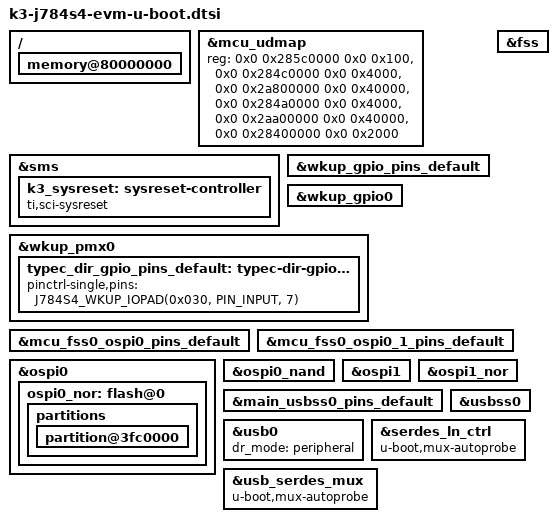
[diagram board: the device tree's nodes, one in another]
// SPDX-License-Identifier: GPL-2.0-only
/*
 * Copyright (C) 2023 Texas Instruments Incorporated - https://www.ti.com/
 */

#include "k3-j784s4-binman.dtsi"

/ {
	memory@80000000 {
		bootph-all;
	};
};

&mcu_udmap {
	reg =   <0x0 0x285c0000 0x0 0x100>,
		<0x0 0x284c0000 0x0 0x4000>,
		<0x0 0x2a800000 0x0 0x40000>,
		<0x0 0x284a0000 0x0 0x4000>,
		<0x0 0x2aa00000 0x0 0x40000>,
		<0x0 0x28400000 0x0 0x2000>;
	reg-names = "gcfg", "rchan", "rchanrt", "tchan",
		    "tchanrt", "rflow";
	bootph-pre-ram;
};

&sms {
	k3_sysreset: sysreset-controller {
		compatible = "ti,sci-sysreset";
		bootph-pre-ram;
	};
};

&wkup_gpio_pins_default {
	bootph-pre-ram;
};

&wkup_gpio0 {
	bootph-pre-ram;
};

&wkup_pmx0 {
	bootph-pre-ram;

	typec_dir_gpio_pins_default: typec-dir-gpio-pins-default {
		pinctrl-single,pins = <
			/* (A33) MCU_OSPI0_CSn1.WKUP_GPIO0_28 */
			J784S4_WKUP_IOPAD(0x030, PIN_INPUT, 7)
		>;
	};
};

&fss {
	bootph-pre-ram;
};

&mcu_fss0_ospi0_pins_default {
	bootph-pre-ram;
};

&mcu_fss0_ospi0_1_pins_default {
	bootph-pre-ram;
};

&ospi0 {
	bootph-pre-ram;

	ospi0_nor: flash@0 {
		bootph-pre-ram;

		partitions {
			bootph-pre-ram;

			partition@3fc0000 {
				bootph-pre-ram;
			};
		};
	};
};

&ospi0_nand {
	bootph-pre-ram;
};

&ospi1 {
	bootph-pre-ram;
};

&ospi1_nor {
	bootph-pre-ram;
};

&main_usbss0_pins_default {
	bootph-pre-ram;
};

&usbss0 {
	bootph-pre-ram;
};

&usb0 {
	dr_mode = "peripheral";
	bootph-pre-ram;
};

&serdes_ln_ctrl {
	u-boot,mux-autoprobe;
};

&usb_serdes_mux {
	u-boot,mux-autoprobe;
};
